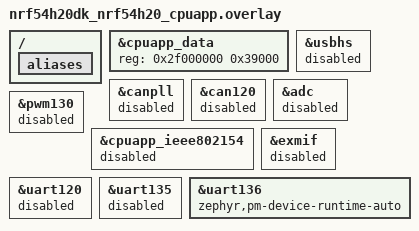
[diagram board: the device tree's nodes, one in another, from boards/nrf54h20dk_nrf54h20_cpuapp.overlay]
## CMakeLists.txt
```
#
# Copyright (c) 2022 Nordic Semiconductor ASA
#
# SPDX-License-Identifier: LicenseRef-Nordic-5-Clause
#
cmake_minimum_required(VERSION 3.20.0)

find_package(Zephyr REQUIRED HINTS $ENV{ZEPHYR_BASE})
project(peripheral_power_profiling)

# NORDIC SDK APP START
target_sources(app PRIVATE
  src/main.c
  src/pwr_service.c
)

if(CONFIG_BT_EXT_ADV)
  target_sources(app PRIVATE src/advertising_ext.c)
else()
  target_sources(app PRIVATE src/advertising_legacy.c)
endif()
# NORDIC SDK APP END
```

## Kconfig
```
#
# Copyright (c) 2022 Nordic Semiconductor
#
# SPDX-License-Identifier: LicenseRef-Nordic-5-Clause
#

source "Kconfig.zephyr"

menu "Nordic Bluetooth power profiling sample"

config BT_POWER_PROFILING_DATA_LENGTH
	int "Notification data length"
	default 20
	range 1 BT_L2CAP_TX_MTU
	help
	  Length of the data sends through notification mechanism.

config BT_POWER_PROFILING_NOTIFICATION_INTERVAL
	int "Notification interval"
	default 500
	help
	  Notification send interval in milliseconds. Notification data is sent on every interval
	  expiration.

config BT_POWER_PROFILING_NOTIFICATION_TIMEOUT
	int "Notification timeout"
	default 10000
	help
	  Notification timeout in milliseconds. When this timeout fires the device will stop
	  sending notifications.

config BT_POWER_PROFILING_CONNECTABLE_ADV_DURATION
	int "Connectable advertising duration"
	default 3000
	help
	  Connectable advertising duration in N*10 milliseconds unit.

config BT_POWER_PROFILING_NON_CONNECTABLE_ADV_DURATION
	int "Non-connectable advertising duration"
	default 6000
	help
	  Non-connectable advertising duration in N*10 milliseconds unit.

config BT_POWER_PROFILING_NFC_ADV_DURATION
	int "Advertising duration when the NFC field is detected"
	default 3000
	help
	  Advertising duration when the NFC field is detected in N*10 milliseconds unit.

config BT_POWER_PROFILING_CONNECTABLE_ADV_INTERVAL_MIN
	int "Connectable advertising minimum interval"
	default 160
	help
	  Connectable advertising minimum interval in 0.625 milliseconds unit.

config BT_POWER_PROFILING_CONNECTABLE_ADV_INTERVAL_MAX
	int "Connectable advertising maximum interval"
	default 240
	help
	  Connectable advertising maximum interval in 0.625 milliseconds unit.

config BT_POWER_PROFILING_NON_CONNECTABLE_ADV_INTERVAL_MIN
	int "Non-connectable advertising minimum interval"
	default 1600
	help
	  Non-connectable advertising minimum interval in 0.625 milliseconds unit.

config BT_POWER_PROFILING_NON_CONNECTABLE_ADV_INTERVAL_MAX
	int "Non-connectable advertising maximum interval"
	default 1920
	help
	  Non-connectable advertising maximum interval in 0.625 milliseconds unit.

config BT_POWER_PROFILING_LED_DISABLED
	bool "Disable LEDs"
	default y
	help
	  Disables the LEDs to reduce power consumption.

config BT_POWER_PROFILING_BUTTONS_DISABLED
	bool "Disable DK buttons"
	help
	  Disables the DK buttons library. Use this on boards where the DK buttons are not
	  usable, for example because they are wired to a GPIO port that cannot be read.

	  The DK buttons library polls the button pins every
	  CONFIG_DK_LIBRARY_BUTTON_SCAN_INTERVAL milliseconds for as long as any button reads
	  as pressed. On a board where a button pin is stuck in the active state, that poll
	  never stops and the periodic wake-ups dominate the measured current consumption.

	  With the buttons disabled, the sample starts connectable advertising right after
	  boot instead of waiting for a button press.

config BT_POWER_PROFILING_NFC_DISABLED
	bool "Disable NFC"
	default y if !HAS_HW_NRF_NFCT
	help
	  Disables the NFC to reduce power consumption.

config SETTINGS
	default y

config ZMS
	default y if (SOC_FLASH_NRF_RRAM || SOC_FLASH_NRF_MRAM)

config NVS
	default y if !(SOC_FLASH_NRF_RRAM || SOC_FLASH_NRF_MRAM)

endmenu
```

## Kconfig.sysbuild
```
#
# Copyright (c) 2023 Nordic Semiconductor
#
# SPDX-License-Identifier: LicenseRef-Nordic-5-Clause
#

config NRF_RADIO_LOADER
	default y if SOC_NRF54H20

config NRF_DEFAULT_IPC_RADIO
	default y

config NETCORE_IPC_RADIO_BT_HCI_IPC
	default y

source "share/sysbuild/Kconfig"
```

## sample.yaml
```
sample:
  description: Bluetooth Low Energy Power Profiling sample
  name: Bluetooth LE Power Profiling
common:
  sysbuild: true
  tags:
    - bluetooth
    - ci_build
    - sysbuild
    - ci_samples_bluetooth
  harness: pytest
  harness_config:
    fixture: ppk_power_measure
    pytest_root:
      - "${CUSTOM_ROOT_TEST_DIR}/test_measure_power_consumption.py::test_measure_and_data_dump_power_54L_ble_power_profiling"
  timeout: 150
tests:
  sample.bluetooth.peripheral_power_profiling:
    build_only: true
    integration_platforms:
      - nrf54l15dk/nrf54l15/cpuapp
      - nrf54ls05dk/nrf54ls05b/cpuapp
      - nrf54h20dk/nrf54h20/cpuapp
    platform_allow:
      - nrf5340dk/nrf5340/cpuapp
      - nrf5340dk/nrf5340/cpuapp/ns
      - nrf54l15dk/nrf54l05/cpuapp
      - nrf54l15dk/nrf54l10/cpuapp
      - nrf54l15dk/nrf54l10/cpuapp/ns
      - nrf54l15dk/nrf54l15/cpuapp
      - nrf54l15dk/nrf54l15/cpuapp/ns
      - nrf54lm20dk/nrf54lm20a/cpuapp
      - nrf54lm20dk/nrf54lm20b/cpuapp
      - nrf54lv10dk/nrf54lv10a/cpuapp
      - nrf54lv10dk/nrf54lv10a/cpuapp/ns
      - nrf54lc10dk/nrf54lc10a/cpuapp
      - nrf54lc10dk/nrf54lc10a/cpuapp/ns
      - nrf54ls05dk/nrf54ls05a/cpuapp
      - nrf54ls05dk/nrf54ls05b/cpuapp
      - nrf54h20dk/nrf54h20/cpuapp
      - nrf7120dk/nrf7120/cpuapp

  sample.bluetooth.peripheral_power_profiling.auto_conn_advert_lfrc_0dBm_100ms:
    tags: &ppk_tag
      - ppk_power_measure
    integration_platforms: &ppk_power_measure_integration_54l_platforms
      - nrf54l15dk/nrf54l15/cpuapp
      - nrf54ls05dk/nrf54ls05b/cpuapp
    platform_allow: &ppk_power_measure_54l_platform_allow
      - nrf54l15dk/nrf54l15/cpuapp
      - nrf54ls05dk/nrf54ls05a/cpuapp
      - nrf54ls05dk/nrf54ls05b/cpuapp
      - nrf54l15dk/nrf54l15/cpuapp/ns
      - nrf54lm20dk/nrf54lm20a/cpuapp
      - nrf54lm20dk/nrf54lm20a/cpuapp/ns
      - nrf54lm20dk/nrf54lm20b/cpuapp
      - nrf54lm20dk/nrf54lm20b/cpuapp/ns
      - nrf54lv10dk/nrf54lv10a/cpuapp
      - nrf54lv10dk/nrf54lv10a/cpuapp/ns
      - nrf54lc10dk/nrf54lc10a/cpuapp
      - nrf54lc10dk/nrf54lc10a/cpuapp/ns
    extra_args:
      - FILE_SUFFIX=auto_conn_advert
      - EXTRA_DTC_OVERLAY_FILE="lfrc.overlay"
      - CONFIG_BT_CTLR_TX_PWR_0=y
      - CONFIG_BT_POWER_PROFILING_DATA_LENGTH=31
      - CONFIG_BT_POWER_PROFILING_NOTIFICATION_INTERVAL=100

  sample.bluetooth.peripheral_power_profiling.auto_conn_advert_lfrc_0dBm_100ms.54h:
    tags: *ppk_tag
    integration_platforms:
      - nrf54h20dk/nrf54h20/cpuapp
    platform_allow:
      - nrf54h20dk/nrf54h20/cpuapp
    extra_args:
      - FILE_SUFFIX=auto_conn_advert
      - CONFIG_BT_CTLR_TX_PWR_0=y
      - CONFIG_BT_POWER_PROFILING_DATA_LENGTH=31
      - CONFIG_BT_POWER_PROFILING_NOTIFICATION_INTERVAL=100
    harness_config:
      fixture: lfclk_at_lfrc
      pytest_root:
        - "${CUSTOM_ROOT_TEST_DIR}/test_measure_power_consumption.py::test_measure_and_data_dump_power_54L_ble_power_profiling"

  sample.bluetooth.peripheral_power_profiling.auto_conn_advert_lfrc_0dBm_30ms:
    tags: *ppk_tag
    integration_platforms: *ppk_power_measure_integration_54l_platforms
    platform_allow: *ppk_power_measure_54l_platform_allow
    extra_args:
      - FILE_SUFFIX=auto_conn_advert
      - EXTRA_DTC_OVERLAY_FILE="lfrc.overlay"
      - CONFIG_BT_CTLR_TX_PWR_0=y
      - CONFIG_BT_POWER_PROFILING_DATA_LENGTH=27
      - CONFIG_BT_POWER_PROFILING_NOTIFICATION_INTERVAL=30

  sample.bluetooth.peripheral_power_profiling.auto_conn_advert_lfrc_0dBm_30ms.54h:
    tags: *ppk_tag
    integration_platforms:
      - nrf54h20dk/nrf54h20/cpuapp
    platform_allow:
      - nrf54h20dk/nrf54h20/cpuapp
    extra_args:
      - FILE_SUFFIX=auto_conn_advert
      - CONFIG_BT_CTLR_TX_PWR_0=y
      - CONFIG_BT_POWER_PROFILING_DATA_LENGTH=27
      - CONFIG_BT_POWER_PROFILING_NOTIFICATION_INTERVAL=30
    harness_config:
      fixture: lfclk_at_lfrc
      pytest_root:
        - "${CUSTOM_ROOT_TEST_DIR}/test_measure_power_consumption.py::test_measure_and_data_dump_power_54L_ble_power_profiling"

  sample.bluetooth.peripheral_power_profiling.auto_conn_advert_lfrc_8dBm_100ms:
    tags: *ppk_tag
    integration_platforms: *ppk_power_measure_integration_54l_platforms
    platform_allow: *ppk_power_measure_54l_platform_allow
    extra_args:
      - FILE_SUFFIX=auto_conn_advert
      - EXTRA_DTC_OVERLAY_FILE="lfrc.overlay"
      - CONFIG_BT_CTLR_TX_PWR_PLUS_8=y
      - CONFIG_BT_POWER_PROFILING_DATA_LENGTH=31
      - CONFIG_BT_POWER_PROFILING_NOTIFICATION_INTERVAL=100

  sample.bluetooth.peripheral_power_profiling.auto_conn_advert_lfrc_8dBm_100ms.54h:
    tags: *ppk_tag
    integration_platforms:
      - nrf54h20dk/nrf54h20/cpuapp
    platform_allow:
      - nrf54h20dk/nrf54h20/cpuapp
    extra_args:
      - FILE_SUFFIX=auto_conn_advert
      - CONFIG_BT_CTLR_TX_PWR_PLUS_8=y
      - CONFIG_BT_POWER_PROFILING_DATA_LENGTH=31
      - CONFIG_BT_POWER_PROFILING_NOTIFICATION_INTERVAL=100
    harness_config:
      fixture: lfclk_at_lfrc
      pytest_root:
        - "${CUSTOM_ROOT_TEST_DIR}/test_measure_power_consumption.py::test_measure_and_data_dump_power_54L_ble_power_profiling"

  sample.bluetooth.peripheral_power_profiling.auto_conn_advert_lfrc_8dBm_30ms:
    tags: *ppk_tag
    integration_platforms: *ppk_power_measure_integration_54l_platforms
    platform_allow: *ppk_power_measure_54l_platform_allow
    extra_args:
      - FILE_SUFFIX=auto_conn_advert
      - EXTRA_DTC_OVERLAY_FILE="lfrc.overlay"
      - CONFIG_BT_CTLR_TX_PWR_PLUS_8=y
      - CONFIG_BT_POWER_PROFILING_DATA_LENGTH=27
      - CONFIG_BT_POWER_PROFILING_NOTIFICATION_INTERVAL=30

  sample.bluetooth.peripheral_power_profiling.auto_conn_advert_lfrc_8dBm_30ms.54h:
    tags: *ppk_tag
    integration_platforms:
      - nrf54h20dk/nrf54h20/cpuapp
    platform_allow:
      - nrf54h20dk/nrf54h20/cpuapp
    extra_args:
      - FILE_SUFFIX=auto_conn_advert
      - CONFIG_BT_CTLR_TX_PWR_PLUS_8=y
      - CONFIG_BT_POWER_PROFILING_DATA_LENGTH=27
      - CONFIG_BT_POWER_PROFILING_NOTIFICATION_INTERVAL=30
    harness_config:
      fixture: lfclk_at_lfrc
      pytest_root:
        - "${CUSTOM_ROOT_TEST_DIR}/test_measure_power_consumption.py::test_measure_and_data_dump_power_54L_ble_power_profiling"

  sample.bluetooth.peripheral_power_profiling.auto_conn_advert_lfxo_0dBm_100ms:
    tags: *ppk_tag
    integration_platforms: &ppk_power_measure_integration_platforms
      - nrf54l15dk/nrf54l15/cpuapp
      - nrf54ls05dk/nrf54ls05b/cpuapp
      - nrf54h20dk/nrf54h20/cpuapp
    platform_allow: &ppk_power_measure_platform_allow
      - nrf54l15dk/nrf54l15/cpuapp
      - nrf54ls05dk/nrf54ls05a/cpuapp
      - nrf54ls05dk/nrf54ls05b/cpuapp
      - nrf54l15dk/nrf54l15/cpuapp/ns
      - nrf54lm20dk/nrf54lm20a/cpuapp
      - nrf54lm20dk/nrf54lm20a/cpuapp/ns
      - nrf54lm20dk/nrf54lm20b/cpuapp
      - nrf54lm20dk/nrf54lm20b/cpuapp/ns
      - nrf54lv10dk/nrf54lv10a/cpuapp
      - nrf54lv10dk/nrf54lv10a/cpuapp/ns
      - nrf54lc10dk/nrf54lc10a/cpuapp
      - nrf54lc10dk/nrf54lc10a/cpuapp/ns
      - nrf54h20dk/nrf54h20/cpuapp
    extra_args:
      - FILE_SUFFIX=auto_conn_advert
      - CONFIG_BT_CTLR_TX_PWR_0=y
      - CONFIG_BT_POWER_PROFILING_DATA_LENGTH=31
      - CONFIG_BT_POWER_PROFILING_NOTIFICATION_INTERVAL=100

  sample.bluetooth.peripheral_power_profiling.auto_conn_advert_lfxo_0dBm_30ms:
    tags: *ppk_tag
    integration_platforms: *ppk_power_measure_integration_platforms
    platform_allow: *ppk_power_measure_platform_allow
    extra_args:
      - FILE_SUFFIX=auto_conn_advert
      - CONFIG_BT_CTLR_TX_PWR_0=y
      - CONFIG_BT_POWER_PROFILING_DATA_LENGTH=27
      - CONFIG_BT_POWER_PROFILING_NOTIFICATION_INTERVAL=30

  sample.bluetooth.peripheral_power_profiling.auto_conn_advert_lfxo_8dBm_100ms:
    tags: *ppk_tag
    integration_platforms: *ppk_power_measure_integration_platforms
    platform_allow: *ppk_power_measure_platform_allow
    extra_args:
      - FILE_SUFFIX=auto_conn_advert
      - CONFIG_BT_CTLR_TX_PWR_PLUS_8=y
      - CONFIG_BT_POWER_PROFILING_DATA_LENGTH=31
      - CONFIG_BT_POWER_PROFILING_NOTIFICATION_INTERVAL=100

  sample.bluetooth.peripheral_power_profiling.auto_conn_advert_lfxo_8dBm_30ms:
    tags: *ppk_tag
    integration_platforms: *ppk_power_measure_integration_platforms
    platform_allow: *ppk_power_measure_platform_allow
    extra_args:
      - FILE_SUFFIX=auto_conn_advert
      - CONFIG_BT_CTLR_TX_PWR_PLUS_8=y
      - CONFIG_BT_POWER_PROFILING_DATA_LENGTH=27
      - CONFIG_BT_POWER_PROFILING_NOTIFICATION_INTERVAL=30

  sample.bluetooth.peripheral_power_profiling.auto_non_conn_advert_lfxo_0dbm_100ms:
    tags: *ppk_tag
    integration_platforms: *ppk_power_measure_integration_platforms
    platform_allow: *ppk_power_measure_platform_allow
    extra_args:
      - FILE_SUFFIX=auto_non_conn_advert
      - CONFIG_BT_CTLR_TX_PWR_0=y
      - CONFIG_BT_POWER_PROFILING_DATA_LENGTH=31
      - CONFIG_BT_POWER_PROFILING_NOTIFICATION_INTERVAL=100

  sample.bluetooth.peripheral_power_profiling.auto_non_conn_advert_lfxo_0dbm_30ms:
    tags: *ppk_tag
    integration_platforms: *ppk_power_measure_integration_platforms
    platform_allow: *ppk_power_measure_platform_allow
    extra_args:
      - FILE_SUFFIX=auto_non_conn_advert
      - CONFIG_BT_CTLR_TX_PWR_0=y
      - CONFIG_BT_POWER_PROFILING_DATA_LENGTH=27
      - CONFIG_BT_POWER_PROFILING_NOTIFICATION_INTERVAL=30

  sample.bluetooth.peripheral_power_profiling.console_log:
    extra_configs:
      - CONFIG_SERIAL=y
      - CONFIG_CONSOLE=y
      - CONFIG_UART_CONSOLE=y
    integration_platforms:
      - nrf54l15dk/nrf54l15/cpuapp
      - nrf54h20dk/nrf54h20/cpuapp
    platform_allow:
      - nrf54h20dk/nrf54h20/cpuapp
      - nrf54l15dk/nrf54l15/cpuapp
      - nrf54l15dk/nrf54l15/cpuapp/ns
      - nrf54lm20dk/nrf54lm20a/cpuapp
      - nrf54lm20dk/nrf54lm20a/cpuapp/ns
      - nrf54lm20dk/nrf54lm20b/cpuapp
      - nrf54lm20dk/nrf54lm20b/cpuapp/ns
      - nrf54ls05dk/nrf54ls05a/cpuapp
      - nrf54ls05dk/nrf54ls05b/cpuapp
      - nrf54lv10dk/nrf54lv10a/cpuapp
      - nrf54lv10dk/nrf54lv10a/cpuapp/ns
      - nrf54lc10dk/nrf54lc10a/cpuapp
      - nrf54lc10dk/nrf54lc10a/cpuapp/ns
    harness: console
    harness_config:
      type: multi_line
      ordered: true
      regex:
        - "Starting Bluetooth Power Profiling sample"
        - "Reset from pin-reset"
    timeout: 30

  sample.bluetooth.peripheral_power_profiling.llvm:
    toolchain_allow: llvm
    integration_platforms:
      - nrf54l15dk/nrf54l15/cpuapp
      - nrf54lm20dk/nrf54lm20a/cpuapp
      - nrf54lm20dk/nrf54lm20b/cpuapp
      - nrf54lv10dk/nrf54lv10a/cpuapp
      - nrf54lc10dk/nrf54lc10a/cpuapp
      - nrf54ls05dk/nrf54ls05b/cpuapp
      - nrf54h20dk/nrf54h20/cpuapp
    platform_allow:
      - nrf54l15dk/nrf54l15/cpuapp
      - nrf54l15dk/nrf54l15/cpuapp/ns
      - nrf54lm20dk/nrf54lm20a/cpuapp
      - nrf54lm20dk/nrf54lm20a/cpuapp/ns
      - nrf54lm20dk/nrf54lm20b/cpuapp
      - nrf54lv10dk/nrf54lv10a/cpuapp
      - nrf54lc10dk/nrf54lc10a/cpuapp
      - nrf54ls05dk/nrf54ls05a/cpuapp
      - nrf54ls05dk/nrf54ls05b/cpuapp
      - nrf54h20dk/nrf54h20/cpuapp
```

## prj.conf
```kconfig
#
# Copyright (c) 2022 Nordic Semiconductor ASA
#
# SPDX-License-Identifier: LicenseRef-Nordic-5-Clause
#

CONFIG_BT=y
CONFIG_BT_SMP=y
CONFIG_BT_SMP_SC_PAIR_ONLY=y
CONFIG_BT_PERIPHERAL=y
CONFIG_BT_DEVICE_NAME="Nordic_Power_Profiling"
CONFIG_BT_EXT_ADV=y
CONFIG_BT_USER_PHY_UPDATE=y
CONFIG_BT_CTLR_PHY_CODED=y

CONFIG_NFC_T2T_NRFXLIB=y

CONFIG_NFC_NDEF=y
CONFIG_NFC_NDEF_MSG=y
CONFIG_NFC_NDEF_RECORD=y
CONFIG_NFC_NDEF_LE_OOB_REC=y
CONFIG_NFC_NDEF_CH_MSG=y

CONFIG_DK_LIBRARY=y

# Enable bonding
CONFIG_BT_SETTINGS=y
CONFIG_FLASH=y
CONFIG_FLASH_PAGE_LAYOUT=y
CONFIG_FLASH_MAP=y

CONFIG_POWEROFF=y

CONFIG_BT_ASSERT=n
CONFIG_ASSERT_MODULE_DEFAULT_LEVEL_NORMAL=y

# Disable UART console by default.
# Comment following lines to bring UART console back.
CONFIG_SERIAL=n
CONFIG_CONSOLE=n
CONFIG_UART_CONSOLE=n
```

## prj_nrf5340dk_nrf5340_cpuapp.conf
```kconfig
#
# Copyright (c) 2022 Nordic Semiconductor ASA
#
# SPDX-License-Identifier: LicenseRef-Nordic-5-Clause
#

CONFIG_NCS_SAMPLES_DEFAULTS=y

CONFIG_BT=y
CONFIG_BT_SMP=y
CONFIG_BT_PERIPHERAL=y
CONFIG_BT_DEVICE_NAME="Nordic_Power_Profiling"
CONFIG_BT_EXT_ADV=y
CONFIG_BT_USER_PHY_UPDATE=y

CONFIG_NFC_T2T_NRFXLIB=y

CONFIG_NFC_NDEF=y
CONFIG_NFC_NDEF_MSG=y
CONFIG_NFC_NDEF_RECORD=y
CONFIG_NFC_NDEF_LE_OOB_REC=y
CONFIG_NFC_NDEF_CH_MSG=y

CONFIG_DK_LIBRARY=y

# Enable bonding
CONFIG_BT_SETTINGS=y
CONFIG_FLASH=y
CONFIG_FLASH_PAGE_LAYOUT=y
CONFIG_FLASH_MAP=y
CONFIG_NVS=y
CONFIG_SETTINGS=y

CONFIG_PM=y
CONFIG_PM_POLICY_CUSTOM=y

CONFIG_MAIN_STACK_SIZE=2048
```

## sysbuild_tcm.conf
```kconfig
#
# Copyright (c) 2025 Nordic Semiconductor ASA
#
# SPDX-License-Identifier: LicenseRef-Nordic-5-Clause
#

# ipc_radio in cpurad TCM via radio_loader; no MCUboot (no signed merge, no DFU).
SB_CONFIG_PPP_IPC_RADIO_TCM=y
SB_CONFIG_NETCORE_REMOTE=y
SB_CONFIG_NRF_RADIO_LOADER=y

SB_CONFIG_BOOTLOADER_NONE=y
SB_CONFIG_BOOTLOADER_MCUBOOT=n
```

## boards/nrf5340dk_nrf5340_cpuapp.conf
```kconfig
#
# Copyright (c) 2022 Nordic Semiconductor ASA
#
# SPDX-License-Identifier: LicenseRef-Nordic-5-Clause
#

CONFIG_BT_CTLR_PHY_CODED=n

# Device power management
CONFIG_PM_DEVICE=y
CONFIG_PM_DEVICE_RUNTIME=y
```

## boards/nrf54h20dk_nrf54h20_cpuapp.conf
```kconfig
#
# Copyright (c) 2025 Nordic Semiconductor ASA
#
# SPDX-License-Identifier: LicenseRef-Nordic-5-Clause
#

# Enable device power management
CONFIG_PM_DEVICE=y
CONFIG_PM_DEVICE_RUNTIME=y

# Enable system power management
CONFIG_PM=y

# Enable power off state
CONFIG_POWEROFF=y

# Enable cpurad for sysbuild
CONFIG_SOC_NRF54H20_CPURAD_ENABLE=y

# MRAM latency optimization - allow MRAM to power off when idle
# This reduces power consumption by allowing MRAM power gating
# CONFIG_MRAM_LATENCY defaults to n, which allows MRAM power gating
CONFIG_MRAM_LATENCY_AUTO_REQ=n

# Peak Current Management
CONFIG_MPSL_FORCE_RRAM_ON_ALL_THE_TIME=n

# For peripheral only softdevice variant, disable Coded PHY support
CONFIG_BT_CTLR_PHY_CODED=n

# PHY update callback not used on this target
CONFIG_BT_USER_PHY_UPDATE=n

# ipc_radio in cpurad TCM: legacy advertising (no extended advertising sets).
CONFIG_BT_EXT_ADV=n
```

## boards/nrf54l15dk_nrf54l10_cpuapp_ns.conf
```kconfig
#
# Copyright (c) 2026 Nordic Semiconductor ASA
#
# SPDX-License-Identifier: LicenseRef-Nordic-5-Clause
#

CONFIG_PM_DEVICE=y
CONFIG_PM_DEVICE_RUNTIME=y

CONFIG_TFM_SFN=y
CONFIG_TFM_NRF_SYSTEM_OFF_SERVICE=y
```

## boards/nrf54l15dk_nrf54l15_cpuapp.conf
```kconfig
#
# Copyright (c) 2024 Nordic Semiconductor
#
# SPDX-License-Identifier: LicenseRef-Nordic-5-Clause
#

# Disable bonding
CONFIG_BT_SETTINGS=n
CONFIG_FLASH=n
CONFIG_FLASH_PAGE_LAYOUT=n
CONFIG_FLASH_MAP=n
CONFIG_NVS=n
CONFIG_SETTINGS=n
```

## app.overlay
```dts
/*
 * Copyright (c) 2024 Nordic Semiconductor ASA
 *
 * SPDX-License-Identifier: LicenseRef-Nordic-5-Clause
 */

/ {
	aliases {
		/delete-property/ sw2;
		/delete-property/ sw3;
	};
};

/delete-node/ &button2;
/delete-node/ &button3;
```

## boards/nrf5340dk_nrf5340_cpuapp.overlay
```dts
/*
 * Copyright (c) 2026 Nordic Semiconductor ASA
 *
 * SPDX-License-Identifier: LicenseRef-Nordic-5-Clause
 */

/* Disable unused peripherals to reduce power consumption */
&adc {
	status = "disabled";
};

&i2c1 {
	status = "disabled";
};

&pwm0 {
	status = "disabled";
};

&uart1 {
	status = "disabled";
};

&qspi {
	status = "disabled";
};

&spi4 {
	status = "disabled";
};

&ieee802154 {
	status = "disabled";
};

&usbd {
	status = "disabled";
};
```

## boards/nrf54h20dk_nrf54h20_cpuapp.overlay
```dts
/*
 * Copyright (c) 2025 Nordic Semiconductor ASA
 *
 * SPDX-License-Identifier: LicenseRef-Nordic-5-Clause
 */

/* CPURAD TCM memory map (radio_loader, no MCUboot). */
#include "../common/memory_map_tcm.dtsi"

&cpuapp_data {
	reg = <0x2f000000 0x39000>;
};

/ {
	aliases {
		/delete-property/ sw2;
		/delete-property/ sw3;
	};
};

/delete-node/ &button2;
/delete-node/ &button3;

/* Disable unused peripherals to reduce power consumption */
&usbhs {
	status = "disabled";
};

&canpll {
	status = "disabled";
};

&can120 {
	status = "disabled";
};

&adc {
	status = "disabled";
};

&pwm130 {
	status = "disabled";
};

&cpuapp_ieee802154 {
	status = "disabled";
};

&exmif {
	status = "disabled";
};

&uart120 {
	status = "disabled";
};

&uart135 {
	status = "disabled";
};

/* Enable PM runtime for uart136 (console UART) */
&uart136 {
	zephyr,pm-device-runtime-auto;
};
```

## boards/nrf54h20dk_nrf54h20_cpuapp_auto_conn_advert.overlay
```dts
/*
 * Copyright (c) 2025 Nordic Semiconductor ASA
 *
 * SPDX-License-Identifier: LicenseRef-Nordic-5-Clause
 */

#include "nrf54h20dk_nrf54h20_cpuapp.overlay"

/ {
	/*
	 * Redefine button0 to use RXD0 - P2.04
	 * Thus, when sending character from host, there will be gpio interrupt,
	 * the same as originally triggered by sw0 button.
	 */
	buttons {
		compatible = "gpio-keys";

		button0: button_0 {
			gpios = <&gpio2 4 (GPIO_PULL_UP | GPIO_ACTIVE_LOW)>;
			label = "Input 0";
			zephyr,code = <INPUT_KEY_0>;
		};
	};
};

&gpio2 {
	status = "okay";
};

&uart136 {
	disable-rx;
};
```

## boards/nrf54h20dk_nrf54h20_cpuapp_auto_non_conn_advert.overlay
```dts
/*
 * Copyright (c) 2025 Nordic Semiconductor ASA
 *
 * SPDX-License-Identifier: LicenseRef-Nordic-5-Clause
 */

#include "nrf54h20dk_nrf54h20_cpuapp.overlay"

/ {
	/*
	 * Redefine button1 to use RXD0 - P2.04
	 * Thus, when sending character from host, there will be gpio interrupt,
	 * the same as originally triggered by sw0 button.
	 */
	buttons {
		compatible = "gpio-keys";

		button1: button_1 {
			gpios = <&gpio2 4 (GPIO_PULL_UP | GPIO_ACTIVE_LOW)>;
			label = "Input 0";
			zephyr,code = <INPUT_KEY_0>;
		};
	};
};

&gpio2 {
	status = "okay";
};

&uart136 {
	disable-rx;
};
```

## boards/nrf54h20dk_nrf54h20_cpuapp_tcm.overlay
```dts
/*
 * Copyright (c) 2025 Nordic Semiconductor ASA
 *
 * SPDX-License-Identifier: LicenseRef-Nordic-5-Clause
 */

/* CPURAD TCM memory map for FILE_SUFFIX=tcm (no MCUboot). */
#include "../common/memory_map_tcm.dtsi"

&cpuapp_data {
	reg = <0x2f000000 0x39000>;
};

/ {
	aliases {
		/delete-property/ sw2;
		/delete-property/ sw3;
	};
};

/delete-node/ &button2;
/delete-node/ &button3;

/* Disable unused peripherals to reduce power consumption */
&usbhs {
	status = "disabled";
};

&canpll {
	status = "disabled";
};

&can120 {
	status = "disabled";
};

&adc {
	status = "disabled";
};

&pwm130 {
	status = "disabled";
};

&cpuapp_ieee802154 {
	status = "disabled";
};

&exmif {
	status = "disabled";
};

&uart120 {
	status = "disabled";
};

&uart135 {
	status = "disabled";
};

/* Enable PM runtime for uart136 (console UART) */
&uart136 {
	zephyr,pm-device-runtime-auto;
};
```

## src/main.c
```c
/*
 * Copyright (c) 2022 Nordic Semiconductor ASA
 *
 * SPDX-License-Identifier: LicenseRef-Nordic-5-Clause
 */

#include <string.h>

#include <zephyr/kernel.h>
#include <zephyr/sys/poweroff.h>
#include <zephyr/pm/device.h>
#include <zephyr/sys/atomic.h>
#include <zephyr/settings/settings.h>

#include <dk_buttons_and_leds.h>

#include <zephyr/bluetooth/bluetooth.h>
#include <zephyr/bluetooth/conn.h>
#include <zephyr/bluetooth/hci.h>

#if !IS_ENABLED(CONFIG_BT_POWER_PROFILING_NFC_DISABLED)
#include <nfc_t2t_lib.h>
#endif /* !IS_ENABLED(CONFIG_BT_POWER_PROFILING_NFC_DISABLED) */
#include <nfc/ndef/msg.h>
#include <nfc/ndef/record.h>
#include <nfc/ndef/ch.h>
#include <nfc/ndef/ch_msg.h>
#include <nfc/ndef/le_oob_rec.h>

#include <helpers/nrfx_reset_reason.h>

#include "advertising.h"
#include "pwr_service.h"

#define RUN_STATUS_LED       DK_LED1
#define CON_STATUS_LED       DK_LED2
#define NFC_FIELD_STATUS_LED DK_LED3

#define CONNECTABLE_ADV_BUTTON     DK_BTN1_MSK
#define NON_CONNECTABLE_ADV_BUTTON DK_BTN2_MSK

#define RUN_LED_BLINK_INTERVAL 1000
#define SYSTEM_OFF_DELAY       5

#define NOTIFICATION_INTERVAL CONFIG_BT_POWER_PROFILING_NOTIFICATION_INTERVAL
#define NOTIFICATION_TIMEOUT  CONFIG_BT_POWER_PROFILING_NOTIFICATION_TIMEOUT

#define NOTIFICATION_PIPELINE_SIZE CONFIG_BT_BUF_ACL_TX_COUNT

#define NFC_BUFFER_SIZE 1024


static struct bt_le_oob oob_local;
#if !IS_ENABLED(CONFIG_BT_POWER_PROFILING_NFC_DISABLED)
static uint8_t nfc_buffer[NFC_BUFFER_SIZE];
static void adv_work_handler(struct k_work *work);
static K_WORK_DEFINE(adv_work, adv_work_handler);
#endif /* !IS_ENABLED(CONFIG_BT_POWER_PROFILING_NFC_DISABLED) */

static void system_off_work_handler(struct k_work *work);
static void key_generation_work_handler(struct k_work *work);
static void notify_work_handler(struct k_work *work);
static void notify_timeout_handler(struct k_work *work);

static K_WORK_DELAYABLE_DEFINE(system_off_work, system_off_work_handler);
static K_WORK_DEFINE(key_generate_work, key_generation_work_handler);
static K_WORK_DELAYABLE_DEFINE(notify_work, notify_work_handler);
static K_WORK_DELAYABLE_DEFINE(notify_timeout, notify_timeout_handler);

static atomic_t notify_pipeline = ATOMIC_INIT(NOTIFICATION_PIPELINE_SIZE);
static struct bt_conn *device_conn;

static int leds_init(void)
{
	if (IS_ENABLED(CONFIG_BT_POWER_PROFILING_LED_DISABLED)) {
		return 0;
	} else {
		return dk_leds_init();
	}
}

static int buttons_init(button_handler_t button_handler)
{
	if (IS_ENABLED(CONFIG_BT_POWER_PROFILING_BUTTONS_DISABLED)) {
		ARG_UNUSED(button_handler);
		return 0;
	} else {
		return dk_buttons_init(button_handler);
	}
}

static void buttons_read(uint32_t *button_state, uint32_t *has_changed)
{
	if (IS_ENABLED(CONFIG_BT_POWER_PROFILING_BUTTONS_DISABLED)) {
		*button_state = CONNECTABLE_ADV_BUTTON;
		*has_changed = CONNECTABLE_ADV_BUTTON;
	} else {
		dk_read_buttons(button_state, has_changed);
	}
}

static int set_led(uint8_t led_idx, uint32_t val)
{
	if (IS_ENABLED(CONFIG_BT_POWER_PROFILING_LED_DISABLED)) {
		ARG_UNUSED(led_idx);
		ARG_UNUSED(val);
		return 0;
	} else {
		return dk_set_led(led_idx, val);
	}
}

static int set_led_on(uint8_t led_idx)
{
	if (IS_ENABLED(CONFIG_BT_POWER_PROFILING_LED_DISABLED)) {
		ARG_UNUSED(led_idx);
		return 0;
	} else {
		return dk_set_led_on(led_idx);
	}
}

static int set_led_off(uint8_t led_idx)
{
	if (IS_ENABLED(CONFIG_BT_POWER_PROFILING_LED_DISABLED)) {
		ARG_UNUSED(led_idx);
		return 0;
	} else {
		return dk_set_led_off(led_idx);
	}
}

#if !IS_ENABLED(CONFIG_BT_POWER_PROFILING_NFC_DISABLED)
static void nfc_callback(void *context, nfc_t2t_event_t event, const uint8_t *data,
			 size_t data_length)
{
	int err;
	static bool adv_permission;

	switch (event) {
	case NFC_T2T_EVENT_FIELD_ON:
		/* Try to cancel system off. */
		err = k_work_cancel_delayable(&system_off_work);
		if (err) {
			/* Action will be continued on system on. */
			return;
		}

		set_led_on(NFC_FIELD_STATUS_LED);
		adv_permission = true;
		break;

	case NFC_T2T_EVENT_FIELD_OFF:
		set_led_off(NFC_FIELD_STATUS_LED);
		break;

	case NFC_T2T_EVENT_DATA_READ:
		if (adv_permission) {
			k_work_submit(&adv_work);
			adv_permission = false;
		}

		break;

	default:
		break;
	}
}
#endif /* !IS_ENABLED(CONFIG_BT_POWER_PROFILING_NFC_DISABLED) */

static void connected(struct bt_conn *conn, uint8_t conn_err)
{
	char addr[BT_ADDR_LE_STR_LEN];

	if (conn_err) {
		printk("Connection failed, err 0x%02x %s\n", conn_err, bt_hci_err_to_str(conn_err));
		return;
	}

	device_conn = conn;

	bt_addr_le_to_str(bt_conn_get_dst(conn), addr, sizeof(addr));
	printk("Connected %s\n", addr);

	set_led_on(CON_STATUS_LED);
}

static void disconnected(struct bt_conn *conn, uint8_t reason)
{
	printk("Disconnected, reason 0x%02x %s\n", reason, bt_hci_err_to_str(reason));

	set_led_off(CON_STATUS_LED);

	atomic_set(&notify_pipeline, NOTIFICATION_PIPELINE_SIZE);

	/* Called from system workqueue context. */
	k_work_cancel_delayable(&notify_work);

	device_conn = NULL;

	/* If there is not any connection, schedule system off. */
	k_work_schedule(&system_off_work, K_SECONDS(1));
}

static void security_changed(struct bt_conn *conn, bt_security_t level, enum bt_security_err err)
{
	char addr[BT_ADDR_LE_STR_LEN];

	bt_addr_le_to_str(bt_conn_get_dst(conn), addr, sizeof(addr));

	if (!err) {
		printk("Security changed: %s level %u\n", addr, level);
	} else {
		printk("Security failed: %s level %u err %d %s\n", addr, level, err,
		       bt_security_err_to_str(err));
	}
}

static void le_param_updated(struct bt_conn *conn, uint16_t interval, uint16_t latency,
			     uint16_t timeout)
{
	printk("Connection parameter updated\n"
	       "Connection interval: 1.25 * %u ms, latency: %u, timeout: 10 * %u ms\n",
	       interval, latency, timeout);
}

#if IS_ENABLED(CONFIG_BT_USER_PHY_UPDATE)
static void le_phy_updated(struct bt_conn *conn, struct bt_conn_le_phy_info *param)
{
	printk("PHY updated, TX: %u RX: %u\n", param->tx_phy, param->rx_phy);
}
#endif /* IS_ENABLED(CONFIG_BT_USER_PHY_UPDATE) */

BT_CONN_CB_DEFINE(connection_cb) = {
	.connected = connected,
	.disconnected = disconnected,
	.security_changed = security_changed,
	.le_param_updated = le_param_updated,
#if IS_ENABLED(CONFIG_BT_USER_PHY_UPDATE)
	.le_phy_updated = le_phy_updated
#endif /* IS_ENABLED(CONFIG_BT_USER_PHY_UPDATE) */
};

static void auth_cancel(struct bt_conn *conn)
{
	char addr[BT_ADDR_LE_STR_LEN];

	bt_addr_le_to_str(bt_conn_get_dst(conn), addr, sizeof(addr));

	printk("Pairing cancelled: %s\n", addr);
}

static void lesc_oob_data_set(struct bt_conn *conn, struct bt_conn_oob_info *info)
{
	int err;
	struct bt_conn_info conn_info;
	char addr[BT_ADDR_LE_STR_LEN];

	if (info->lesc.oob_config != BT_CONN_OOB_LOCAL_ONLY) {
		printk("Unsupported OOB request\n");
		return;
	}

	err = bt_conn_get_info(conn, &conn_info);
	if (err) {
		printk("Failed to get conn info (err %d)\n", err);
		return;
	}

	if (bt_addr_le_cmp(conn_info.le.local, &oob_local.addr) != 0) {
		bt_addr_le_to_str(conn_info.le.local, addr, sizeof(addr));
		printk("No OOB data available for local %s", addr);
		bt_conn_auth_cancel(conn);
		return;
	}

	err = bt_le_oob_set_sc_data(conn, &oob_local.le_sc_data, NULL);
	if (err) {
		printk("Failed to set OOB SC local data (err %d)\n", err);
	}
}

static void oob_data_request(struct bt_conn *conn, struct bt_conn_oob_info *info)
{
	if (info->type == BT_CONN_OOB_LE_SC) {
		printk("LESC OOB data requested\n");
		lesc_oob_data_set(conn, info);
	}
}

static const struct bt_conn_auth_cb conn_auth_callbacks = {
	.cancel = auth_cancel,
	.oob_data_request = oob_data_request
};

static void pairing_complete(struct bt_conn *conn, bool bonded)
{
	char addr[BT_ADDR_LE_STR_LEN];

	bt_addr_le_to_str(bt_conn_get_dst(conn), addr, sizeof(addr));

	printk("Pairing completed: %s, bonded: %d\n", addr, bonded);

	/* Generate new pairing keys if pairing procedure succeed. */
	k_work_submit(&key_generate_work);
}

static void pwr_notify_sent_cb(struct bt_conn *conn, void *user_data)
{
	atomic_inc(&notify_pipeline);
}

static void pwr_notify_status_cb(enum pwr_service_status status, void *user_data)
{
	switch (status) {
	case PWR_SERVICE_STATUS_NOTIFY_ENABLED:
		k_work_schedule(&notify_timeout, K_MSEC(NOTIFICATION_TIMEOUT));
		k_work_schedule(&notify_work, K_NO_WAIT);

		printk("Notification enabled\n");

		break;

	case PWR_SERVICE_STATUS_NOTIFY_DISABLED:
		/* Called from cooperative thread context. */
		k_work_cancel_delayable(&notify_work);
		k_work_cancel_delayable(&notify_timeout);

		printk("Notification disabled\n");

		break;

	default:
		/* Should not happen. */
		__ASSERT_NO_MSG(false);
		break;
	}
}

static const struct pwr_service_cb pwr_service_callback = {
	.sent_cb = pwr_notify_sent_cb,
	.notify_status_cb = pwr_notify_status_cb,
};

static void pairing_failed(struct bt_conn *conn, enum bt_security_err reason)
{
	char addr[BT_ADDR_LE_STR_LEN];

	bt_addr_le_to_str(bt_conn_get_dst(conn), addr, sizeof(addr));

	printk("Pairing failed conn: %s, reason %d %s\n", addr, reason,
	       bt_security_err_to_str(reason));

	/* Generate new pairing keys if pairing procedure failed. */
	k_work_submit(&key_generate_work);
}

static struct bt_conn_auth_info_cb conn_auth_info_callbacks = {
	.pairing_complete = pairing_complete,
	.pairing_failed = pairing_failed,
};

static void button_handler(uint32_t button_state, uint32_t has_changed)
{
	int err;
	uint32_t buttons = button_state & has_changed;

	if (buttons & CONNECTABLE_ADV_BUTTON) {
		k_work_cancel_delayable(&system_off_work);

		err = advertising_start_connectable();
		if (err) {
			printk("Connectable advertising failed to start (err %d)\n", err);
		} else {
			printk("Connectable advertising started\n");
		}

		return;
	}

	if (buttons & NON_CONNECTABLE_ADV_BUTTON) {
		k_work_cancel_delayable(&system_off_work);

		err = advertising_start_non_connectable();
		if (err) {
			printk("Non-connectable advertising failed to start (err %d)\n", err);
		} else {
			printk("Non-connectable advertising started\n");
		}

		return;
	}
}

static int pairing_key_generate(void)
{
	int err;

	err = bt_le_oob_get_local(BT_ID_DEFAULT, &oob_local);
	if (err) {
		printk("Failed to get local oob data (err %d)\n", err);
		return err;
	}

	return err;
}

static void key_generation_work_handler(struct k_work *work)
{
	pairing_key_generate();
}

#if !IS_ENABLED(CONFIG_BT_POWER_PROFILING_NFC_DISABLED)
static void adv_work_handler(struct k_work *work)
{
	int err;

	/* Called from workqueue context. */
	k_work_cancel_delayable(&system_off_work);

	err = advertising_start_connectable_nfc();
	if (err) {
		printk("Connectable advertising failed to start (err %d)\n", err);
	} else {
		printk("Connectable advertising started\n");
	}
}
#endif /* !IS_ENABLED(CONFIG_BT_POWER_PROFILING_NFC_DISABLED) */

static void notify_work_handler(struct k_work *work)
{
	int err;
	atomic_val_t pipeline = atomic_get(&notify_pipeline);

	if (pipeline == 0) {
		/* There is no place for notification in Bluetooth stack, skip sending notification,
		 * and schedule the new interval.
		 */
		printk("Notification cannot be passed to Bluetooth stack\n");
		k_work_reschedule(k_work_delayable_from_work(work), K_MSEC(NOTIFICATION_INTERVAL));
		return;
	}

	err = pwr_service_notify(NULL);
	if (err) {
		printk("Failed to send PWR service notification (err %d)\n", err);
	} else {
		atomic_dec(&notify_pipeline);
	}

	k_work_reschedule(k_work_delayable_from_work(work), K_MSEC(NOTIFICATION_INTERVAL));
}

static void notify_timeout_handler(struct k_work *work)
{
	int err;

	if (device_conn) {
		k_work_cancel_delayable(&notify_work);

		printk("Notification sending ended. Disconnecting...\n");

		err = bt_conn_disconnect(device_conn, BT_HCI_ERR_REMOTE_USER_TERM_CONN);
		if (err) {
			printk("Failed to disconnect Bluetooth link (err %d)\n", err);
		}
	}
}

#if !IS_ENABLED(CONFIG_BT_POWER_PROFILING_NFC_DISABLED)
static int nfc_oob_data_setup(size_t *size)
{
	static const uint8_t ndef_record_count = 2;
	static const uint8_t ch_record_count = 1;

	int err;
	struct nfc_ndef_le_oob_rec_payload_desc oob_rec_payload;
	struct nfc_ndef_ch_msg_records ch_msg_records;

	NFC_NDEF_MSG_DEF(ndef_msg, ndef_record_count);

	NFC_NDEF_LE_OOB_RECORD_DESC_DEF(oob_rec, '0', &oob_rec_payload);
	NFC_NDEF_CH_AC_RECORD_DESC_DEF(ac_rec, NFC_AC_CPS_ACTIVE, 1, "0", 0);
	NFC_NDEF_CH_HS_RECORD_DESC_DEF(hs_record, NFC_NDEF_CH_MSG_MAJOR_VER,
				       NFC_NDEF_CH_MSG_MINOR_VER, ch_record_count);

	memset(&oob_rec_payload, 0, sizeof(oob_rec_payload));

	oob_rec_payload.addr = &oob_local.addr;
	oob_rec_payload.appearance = NFC_NDEF_LE_OOB_REC_APPEARANCE(bt_get_appearance());
	oob_rec_payload.flags = NFC_NDEF_LE_OOB_REC_FLAGS(BT_LE_AD_NO_BREDR);
	oob_rec_payload.le_role =
			NFC_NDEF_LE_OOB_REC_LE_ROLE(NFC_NDEF_LE_OOB_REC_LE_ROLE_PERIPH_ONLY);
	oob_rec_payload.le_sc_data = &oob_local.le_sc_data;
	oob_rec_payload.local_name = bt_get_name();

	ch_msg_records.ac = &NFC_NDEF_CH_AC_RECORD_DESC(ac_rec);
	ch_msg_records.carrier = &NFC_NDEF_LE_OOB_RECORD_DESC(oob_rec);
	ch_msg_records.cnt = ch_record_count;

	err = nfc_ndef_ch_msg_hs_create(&NFC_NDEF_MSG(ndef_msg),
					&NFC_NDEF_CH_RECORD_DESC(hs_record), &ch_msg_records);
	if (err) {
		printk("Failed to create Connection Handover NDEF message (err %d)\n", err);
		return err;
	}

	return nfc_ndef_msg_encode(&NFC_NDEF_MSG(ndef_msg), nfc_buffer, size);
}
#endif /* !IS_ENABLED(CONFIG_BT_POWER_PROFILING_NFC_DISABLED) */

static int nfc_init(void)
{
#if !IS_ENABLED(CONFIG_BT_POWER_PROFILING_NFC_DISABLED)
	int err;
	size_t nfc_buffer_size = sizeof(nfc_buffer);

	err = nfc_t2t_setup(nfc_callback, NULL);
	if (err) {
		printk("Failed to setup NFC T2T library (err %d)\n", err);
		return err;
	}

	err = nfc_oob_data_setup(&nfc_buffer_size);
	if (err) {
		printk("Failed to setup NFC OOB data (err %d)\n", err);
		return err;
	}

	err = nfc_t2t_payload_set(nfc_buffer, nfc_buffer_size);
	if (err) {
		printk("Failed to set NFC T2T payload (err %d)\n", err);
		return err;
	}

	err = nfc_t2t_emulation_start();
	if (err) {
		printk("Failed to start NFC T2T emulation (err %d)\n", err);
	}

	return err;
#else
	return 0;
#endif /* !IS_ENABLED(CONFIG_BT_POWER_PROFILING_NFC_DISABLED) */
}

static void reset_reason_print(void)
{
	uint32_t reason;

	reason = nrfx_reset_reason_get();

	if (reason & NRFX_RESET_REASON_OFF_MASK) {
		printk("Wake up by the advertising start buttons\n");
#if !IS_ENABLED(CONFIG_BT_POWER_PROFILING_NFC_DISABLED)
	} else if (reason & NRFX_RESET_REASON_NFC_MASK) {
		printk("Wake up by NFC field detected\n");
#endif /* !IS_ENABLED(CONFIG_BT_POWER_PROFILING_NFC_DISABLED) */
#if defined(NRF_RESETINFO)
	} else if (reason & NRFX_RESET_REASON_LOCAL_SREQ_MASK) {
		printk("Application soft reset detected\n");
#else
	} else if (reason & NRFX_RESET_REASON_SREQ_MASK) {
		printk("Application soft reset detected\n");
#endif /* defined(NRF_RESETINFO) */
	} else if (reason & NRFX_RESET_REASON_RESETPIN_MASK) {
		printk("Reset from pin-reset\n");
	} else if (reason) {
		printk("System reset from different reason 0x%08X\n", reason);
	} else {
		printk("Power-on reset\n");
	}
}

static void system_off(void)
{
#if !IS_ENABLED(CONFIG_SOC_SERIES_NRF54H)
	printk("Powering off\n");

	/* Clear the reset reason if it didn't do previously. */
	nrfx_reset_reason_clear(nrfx_reset_reason_get());

	set_led_off(RUN_STATUS_LED);

	if (IS_ENABLED(CONFIG_PM_DEVICE) && IS_ENABLED(CONFIG_SERIAL)) {
		static const struct device *dev = DEVICE_DT_GET(DT_CHOSEN(zephyr_console));
		int err;
		enum pm_device_state state;

		if (dev) {
			do {
				err = pm_device_state_get(dev, &state);
			} while ((err == 0) && (state == PM_DEVICE_STATE_ACTIVE));
		}
	}

	sys_poweroff();
#endif /* !IS_ENABLED(CONFIG_SOC_SERIES_NRF54H) */
}

static void system_off_work_handler(struct k_work *work)
{
	system_off();
}

static void on_adv_terminated(void)
{
	if (!device_conn) {
		printk("Advertising terminated.\n");
#if !IS_ENABLED(CONFIG_SOC_SERIES_NRF54H)
		printk("Scheduling system off\n");

		k_work_schedule(&system_off_work, K_SECONDS(1));
#endif /* !IS_ENABLED(CONFIG_SOC_SERIES_NRF54H) */
	}
}

static const struct advertising_cb adv_module_cb = {
	.terminated = on_adv_terminated,
};

int main(void)
{
	int err;
	uint32_t blink_status = 0;
	uint32_t button_state = 0;
	uint32_t has_changed = 0;

	printk("Starting Bluetooth Power Profiling sample\n");

	err = buttons_init(button_handler);
	if (err) {
		printk("Failed to initialize buttons (err %d)\n", err);
		return 0;
	}

	/* Read the button state after booting to check if advertising start is needed. */
	buttons_read(&button_state, &has_changed);

	err = leds_init();
	if (err) {
		printk("LEDs init failed (err %d)\n", err);
		return 0;
	}

	reset_reason_print();

	err = pwr_service_cb_register(&pwr_service_callback, NULL);
	if (err) {
		printk("Failed to register PWR service callback (err %d)\n", err);
		return 0;
	}

	err = bt_enable(NULL);
	if (err) {
		printk("Bluetooth init failed (err %d)\n", err);
		return 0;
	}

	if (IS_ENABLED(CONFIG_SETTINGS)) {
		err = settings_load();
		if (err) {
			printk("Failed to load settings (err %d)\n", err);
			return 0;
		}
	}

	err = bt_conn_auth_info_cb_register(&conn_auth_info_callbacks);
	if (err) {
		printk("Failed to register authorization info callbacks (err %d)\n", err);
		return 0;
	}

	err = bt_conn_auth_cb_register(&conn_auth_callbacks);
	if (err) {
		printk("Failed to register authorization callbacks (err %d)\n", err);
		return 0;
	}

	err = advertising_init(&adv_module_cb);
	if (err) {
		printk("Failed to initialize advertising (err %d)\n", err);
		return 0;
	}

	err = pairing_key_generate();
	if (err) {
		printk("Failed to generate pairing keys (err %d)\n", err);
		return 0;
	}

	if (!IS_ENABLED(CONFIG_BT_POWER_PROFILING_NFC_DISABLED)) {
		err = nfc_init();
		if (err) {
			printk("Failed to initialize NFC (err %d)\n", err);
			return 0;
		}
	}

	button_handler(button_state, has_changed);

	if (!(button_state & (CONNECTABLE_ADV_BUTTON | NON_CONNECTABLE_ADV_BUTTON))) {
		k_work_schedule(&system_off_work, K_SECONDS(SYSTEM_OFF_DELAY));
	}

	if (!IS_ENABLED(CONFIG_BT_POWER_PROFILING_LED_DISABLED)) {
		for (;;) {
			set_led(RUN_STATUS_LED, (++blink_status) % 2);
			k_sleep(K_MSEC(RUN_LED_BLINK_INTERVAL));
		}
	} else {
		return 0;
	}
}
```

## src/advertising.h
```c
/*
 * Copyright (c) 2026 Nordic Semiconductor ASA
 *
 * SPDX-License-Identifier: LicenseRef-Nordic-5-Clause
 */

#ifndef ADVERTISING_H_
#define ADVERTISING_H_

#ifdef __cplusplus
extern "C" {
#endif

/**
 * @brief Invoked when advertising stops due to duration timeout (no connection).
 *
 * @note The Bluetooth stack may invoke this from a cooperative context.
 */
typedef void (*advertising_terminated_cb_t)(void);

/**
 * @brief Advertising module callbacks.
 *
 * Keep this structure for future extensions; new fields must be appended.
 */
struct advertising_cb {
	/** Called when connectable or non-connectable advertising times out. */
	advertising_terminated_cb_t terminated;
};

/**
 * @brief Initialize the advertising module.
 *
 * Must be called after @ref bt_enable. Creates resources (for example, extended advertising set)
 * when @kconfig{CONFIG_BT_EXT_ADV} is enabled; otherwise uses legacy advertising.
 *
 * Durations and intervals are taken from Kconfig:
 * - @kconfig{CONFIG_BT_POWER_PROFILING_CONNECTABLE_ADV_DURATION}
 * - @kconfig{CONFIG_BT_POWER_PROFILING_NON_CONNECTABLE_ADV_DURATION}
 * - @kconfig{CONFIG_BT_POWER_PROFILING_NFC_ADV_DURATION}
 * - @kconfig{CONFIG_BT_POWER_PROFILING_CONNECTABLE_ADV_INTERVAL_MIN} / _MAX
 * - @kconfig{CONFIG_BT_POWER_PROFILING_NON_CONNECTABLE_ADV_INTERVAL_MIN} / _MAX
 *
 * @param[in] cb Callbacks. Must remain valid for the lifetime of the module.
 *
 * @retval 0 Success.
 * @retval -EINVAL @p cb is NULL or a required callback is missing.
 * @retval -EALREADY Already initialized.
 * @retval Negative errno Other error from the implementation.
 */
int advertising_init(const struct advertising_cb *cb);

/**
 * @brief Start connectable advertising.
 *
 * Stops any ongoing advertising first. Duration is
 * @kconfig{CONFIG_BT_POWER_PROFILING_CONNECTABLE_ADV_DURATION}
 * (N × 10 ms units for each Zephyr API).
 *
 * @retval 0 Success.
 * @retval -EINVAL Module not initialized.
 * @retval Negative errno Error from the Bluetooth stack or implementation.
 */
int advertising_start_connectable(void);

/**
 * @brief Start connectable advertising for the NFC handover path.
 *
 * Same as @ref advertising_start_connectable except duration is
 * @kconfig{CONFIG_BT_POWER_PROFILING_NFC_ADV_DURATION}.
 *
 * @retval 0 Success.
 * @retval -EINVAL Module not initialized.
 * @retval Negative errno Error from the Bluetooth stack or implementation.
 */
int advertising_start_connectable_nfc(void);

/**
 * @brief Start non-connectable advertising.
 *
 * Stops any ongoing advertising first. Duration is
 * @kconfig{CONFIG_BT_POWER_PROFILING_NON_CONNECTABLE_ADV_DURATION}.
 *
 * @retval 0 Success.
 * @retval -EINVAL Module not initialized.
 * @retval Negative errno Error from the Bluetooth stack or implementation.
 */
int advertising_start_non_connectable(void);

/**
 * @brief Stop advertising.
 *
 * @retval 0 Success (including if advertising was already stopped).
 * @retval Negative errno Error from the Bluetooth stack or implementation.
 */
int advertising_stop(void);

#ifdef __cplusplus
}
#endif

#endif /* ADVERTISING_H_ */
```

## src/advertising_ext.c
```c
/*
 * Copyright (c) 2026 Nordic Semiconductor ASA
 *
 * SPDX-License-Identifier: LicenseRef-Nordic-5-Clause
 */

#include <errno.h>
#include <stdbool.h>

#include <zephyr/bluetooth/bluetooth.h>
#include <zephyr/kernel.h>
#include <zephyr/sys/util.h>

#include "advertising.h"

static struct bt_le_ext_adv *adv_set;
static const struct advertising_cb *adv_cb;
static bool initialized;

static const struct bt_data connectable_ad_data[] = {
	BT_DATA_BYTES(BT_DATA_FLAGS, (BT_LE_AD_GENERAL | BT_LE_AD_NO_BREDR)),
	BT_DATA(BT_DATA_NAME_COMPLETE, CONFIG_BT_DEVICE_NAME, sizeof(CONFIG_BT_DEVICE_NAME) - 1),
};

static const struct bt_data non_connectable_ad_data[] = {
	BT_DATA_BYTES(BT_DATA_FLAGS, BT_LE_AD_NO_BREDR),
	BT_DATA_BYTES(BT_DATA_URI, /* The URI of the https://www.nordicsemi.com website */
		      0x17,	   /* UTF-8 code point for "https:" */
		      '/', '/', 'w', 'w', 'w', '.', 'n', 'o', 'r', 'd', 'i', 'c', 's', 'e', 'm',
		      'i', '.', 'c', 'o', 'm'),
};

static const struct bt_le_adv_param *connectable_ad_params =
	BT_LE_ADV_PARAM(BT_LE_ADV_OPT_CONN, CONFIG_BT_POWER_PROFILING_CONNECTABLE_ADV_INTERVAL_MIN,
			CONFIG_BT_POWER_PROFILING_CONNECTABLE_ADV_INTERVAL_MAX, NULL);

static const struct bt_le_adv_param *non_connectable_ad_params = BT_LE_ADV_PARAM(
	BT_LE_ADV_OPT_NONE, CONFIG_BT_POWER_PROFILING_NON_CONNECTABLE_ADV_INTERVAL_MIN,
	CONFIG_BT_POWER_PROFILING_NON_CONNECTABLE_ADV_INTERVAL_MAX, NULL);

static void adv_sent(struct bt_le_ext_adv *adv, struct bt_le_ext_adv_sent_info *info)
{
	ARG_UNUSED(adv);
	ARG_UNUSED(info);

	if (adv_cb && adv_cb->terminated) {
		adv_cb->terminated();
	}
}

static const struct bt_le_ext_adv_cb adv_callbacks = {
	.sent = adv_sent,
};

static int start_connectable(uint16_t timeout)
{
	int err;
	struct bt_le_ext_adv_start_param ext_start_param = {
		.timeout = timeout,
		.num_events = 0,
	};

	(void)bt_le_ext_adv_stop(adv_set);
	err = bt_le_ext_adv_update_param(adv_set, connectable_ad_params);
	if (err) {
		return err;
	}

	err = bt_le_ext_adv_set_data(adv_set, connectable_ad_data, ARRAY_SIZE(connectable_ad_data),
				     NULL, 0);
	if (err) {
		return err;
	}

	return bt_le_ext_adv_start(adv_set, &ext_start_param);
}

static int start_non_connectable(uint16_t timeout)
{
	int err;
	struct bt_le_ext_adv_start_param ext_start_param = {
		.timeout = timeout,
		.num_events = 0,
	};

	(void)bt_le_ext_adv_stop(adv_set);
	err = bt_le_ext_adv_update_param(adv_set, non_connectable_ad_params);
	if (err) {
		return err;
	}

	err = bt_le_ext_adv_set_data(adv_set, non_connectable_ad_data,
				     ARRAY_SIZE(non_connectable_ad_data), NULL, 0);
	if (err) {
		return err;
	}

	return bt_le_ext_adv_start(adv_set, &ext_start_param);
}

int advertising_init(const struct advertising_cb *cb)
{
	int err;

	if (!cb || !cb->terminated) {
		return -EINVAL;
	}

	if (initialized) {
		return -EALREADY;
	}

	adv_cb = cb;

	err = bt_le_ext_adv_create(connectable_ad_params, &adv_callbacks, &adv_set);
	if (err) {
		return err;
	}

	initialized = true;

	return 0;
}

int advertising_start_connectable(void)
{
	if (!initialized) {
		return -EINVAL;
	}

	return start_connectable(CONFIG_BT_POWER_PROFILING_CONNECTABLE_ADV_DURATION);
}

int advertising_start_connectable_nfc(void)
{
	if (!initialized) {
		return -EINVAL;
	}

	return start_connectable(CONFIG_BT_POWER_PROFILING_NFC_ADV_DURATION);
}

int advertising_start_non_connectable(void)
{
	if (!initialized) {
		return -EINVAL;
	}

	return start_non_connectable(CONFIG_BT_POWER_PROFILING_NON_CONNECTABLE_ADV_DURATION);
}

int advertising_stop(void)
{
	if (!initialized || !adv_set) {
		return 0;
	}

	return bt_le_ext_adv_stop(adv_set);
}
```

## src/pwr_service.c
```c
/*
 * Copyright (c) 2022 Nordic Semiconductor ASA
 *
 * SPDX-License-Identifier: LicenseRef-Nordic-5-Clause
 */

#include <zephyr/bluetooth/uuid.h>
#include <zephyr/bluetooth/gatt.h>

#include "pwr_service.h"

#define PWR_SERVICE_UUID_VAL BT_UUID_128_ENCODE(0x00001630, 0x1212, 0xEFDE, 0x1523, 0x785FEABCD123)
#define PWR_CHAR_UUID_VAL BT_UUID_128_ENCODE(0x00001630, 0x1212, 0xEFDE, 0x1524, 0x785FEABCD123)

#define PWR_SERVICE_UUID BT_UUID_DECLARE_128(PWR_SERVICE_UUID_VAL)
#define PWR_CHAR_UUID BT_UUID_DECLARE_128(PWR_CHAR_UUID_VAL)

#define PWR_CHAR_ATTR_IDX 2

static const struct pwr_service_cb *pwr_cb;
static void *pwr_cb_user_data;
static uint8_t notify_data[CONFIG_BT_POWER_PROFILING_DATA_LENGTH];

static ssize_t pwr_char_read(struct bt_conn *conn, const struct bt_gatt_attr *attr,
			     void *buf, uint16_t len, uint16_t offset)
{

	return bt_gatt_attr_read(conn, attr, buf, len, offset, notify_data, sizeof(notify_data));
}

static void cccd_changed(const struct bt_gatt_attr *attr, uint16_t value)
{
	bool notify_enabled = (value == BT_GATT_CCC_NOTIFY);

	if (pwr_cb->notify_status_cb) {
		pwr_cb->notify_status_cb(notify_enabled ? PWR_SERVICE_STATUS_NOTIFY_ENABLED :
							  PWR_SERVICE_STATUS_NOTIFY_DISABLED,
					 pwr_cb_user_data);
	}
}

BT_GATT_SERVICE_DEFINE(pwr_svc,
	BT_GATT_PRIMARY_SERVICE(PWR_SERVICE_UUID),
	BT_GATT_CHARACTERISTIC(PWR_CHAR_UUID,
			       (BT_GATT_CHRC_READ | BT_GATT_CHRC_NOTIFY),
			       (BT_GATT_PERM_READ),
			       pwr_char_read, NULL, NULL),
	BT_GATT_CCC(cccd_changed, BT_GATT_PERM_READ | BT_GATT_PERM_WRITE)
);

static void pwr_service_notify_complete(struct bt_conn *conn, void *user_data)
{
	if (pwr_cb->sent_cb) {
		pwr_cb->sent_cb(conn, pwr_cb_user_data);
	}
}

int pwr_service_notify(struct bt_conn *conn)
{
	const struct bt_gatt_attr *attr = &pwr_svc.attrs[PWR_CHAR_ATTR_IDX];
	struct bt_gatt_notify_params params;

	memset(&params, 0, sizeof(params));

	params.attr = attr;
	params.data = notify_data;
	params.len = sizeof(notify_data);
	params.func = pwr_service_notify_complete;

	if (!conn) {
		return bt_gatt_notify_cb(NULL, &params);
	} else if (bt_gatt_is_subscribed(conn, attr, BT_GATT_CCC_NOTIFY)) {
		return bt_gatt_notify_cb(conn, &params);
	} else {
		return -EINVAL;
	}
}

int pwr_service_cb_register(const struct pwr_service_cb *cb, void *user_data)
{
	if (pwr_cb) {
		return -EALREADY;
	}

	pwr_cb = cb;
	pwr_cb_user_data = user_data;

	return 0;
}
```
